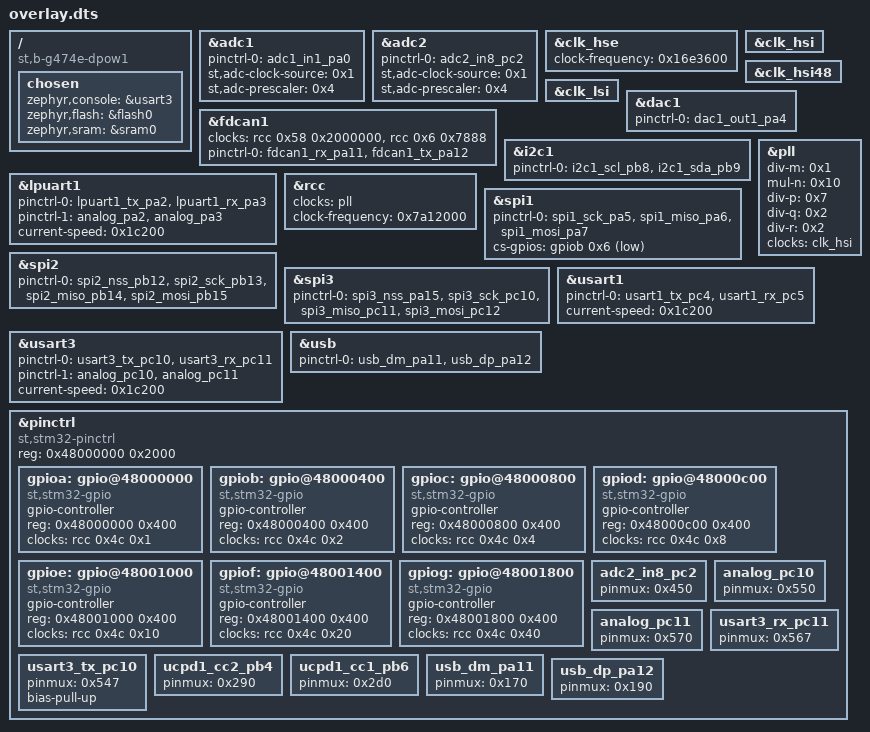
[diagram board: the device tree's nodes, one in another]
/ {
	compatible = "st,b-g474e-dpow1";
	chosen {
		zephyr,console = &usart3;
		zephyr,flash = &flash0;
		zephyr,sram = &sram0;
	};
};
&adc1{
	status = "okay";
	pinctrl-0 = < &adc1_in1_pa0 >;
	pinctrl-names = "default";
	st,adc-clock-source = < 0x1 >;
	st,adc-prescaler = < 0x4 >;
};
&adc2{
	status = "okay";
	pinctrl-0 = < &adc2_in8_pc2 >;
	pinctrl-names = "default";
	st,adc-clock-source = < 0x1 >;
	st,adc-prescaler = < 0x4 >;
	#address-cells = < 0x1 >;
	#size-cells = < 0x0 >;
};
&clk_hse{
	status = "okay";
	clock-frequency = < 0x16e3600 >;
};
&clk_hsi{
	status = "okay";
};
&clk_hsi48{
	status = "okay";
};
&clk_lsi{
	status = "okay";
};
&dac1{
	status = "okay";
	pinctrl-0 = < &dac1_out1_pa4 >;
	pinctrl-names = "default";
};
&fdcan1{
	clocks = < &rcc 0x58 0x2000000 >, < &rcc 0x6 0x7888 >;
	status = "okay";
	pinctrl-0 = < &fdcan1_rx_pa11 &fdcan1_tx_pa12 >;
	pinctrl-names = "default";
};
&i2c1{
	status = "okay";
	pinctrl-0 = < &i2c1_scl_pb8 &i2c1_sda_pb9 >;
	pinctrl-names = "default";
};
&lpuart1{
	status = "okay";
	pinctrl-0 = < &lpuart1_tx_pa2 &lpuart1_rx_pa3 >;
	pinctrl-1 = < &analog_pa2 &analog_pa3 >;
	pinctrl-names = "default", "sleep";
	current-speed = < 0x1c200 >;
};
&pll{
	status = "okay";
	div-m = < 0x1 >;
	mul-n = < 0x10 >;
	div-p = < 0x7 >;
	div-q = < 0x2 >;
	div-r = < 0x2 >;
	clocks = < &clk_hsi >;
};
&rcc{
	clocks = < &pll >;
	clock-frequency = < 0x7a12000 >;
};
&spi1{
	status = "okay";
	pinctrl-0 = < &spi1_sck_pa5 &spi1_miso_pa6 &spi1_mosi_pa7 >;
	pinctrl-names = "default";
	cs-gpios = < &gpiob 0x6 0x11 >;
};
&spi2{
	status = "okay";
	pinctrl-0 = < &spi2_nss_pb12 &spi2_sck_pb13 &spi2_miso_pb14 &spi2_mosi_pb15 >;
	pinctrl-names = "default";
};
&spi3{
	status = "okay";
	pinctrl-0 = < &spi3_nss_pa15 &spi3_sck_pc10 &spi3_miso_pc11 &spi3_mosi_pc12 >;
	pinctrl-names = "default";
};
&usart1{
	status = "okay";
	pinctrl-0 = < &usart1_tx_pc4 &usart1_rx_pc5 >;
	pinctrl-names = "default";
	current-speed = < 0x1c200 >;
};
&usart3{
	status = "okay";
	pinctrl-0 = < &usart3_tx_pc10 &usart3_rx_pc11 >;
	pinctrl-1 = < &analog_pc10 &analog_pc11 >;
	pinctrl-names = "default", "sleep";
	current-speed = < 0x1c200 >;
};
&usb{
	status = "okay";
	pinctrl-0 = < &usb_dm_pa11 &usb_dp_pa12 >;
	pinctrl-names = "default";
};
&pinctrl{
	compatible = "st,stm32-pinctrl";
	#address-cells = < 0x1 >;
	#size-cells = < 0x1 >;
	reg = < 0x48000000 0x2000 >;
	gpioa: gpio@48000000 {
		compatible = "st,stm32-gpio";
		gpio-controller;
		#gpio-cells = < 0x2 >;
		reg = < 0x48000000 0x400 >;
		clocks = < &rcc 0x4c 0x1 >;
	};
	gpiob: gpio@48000400 {
		compatible = "st,stm32-gpio";
		gpio-controller;
		#gpio-cells = < 0x2 >;
		reg = < 0x48000400 0x400 >;
		clocks = < &rcc 0x4c 0x2 >;
	};
	gpioc: gpio@48000800 {
		compatible = "st,stm32-gpio";
		gpio-controller;
		#gpio-cells = < 0x2 >;
		reg = < 0x48000800 0x400 >;
		clocks = < &rcc 0x4c 0x4 >;
	};
	gpiod: gpio@48000c00 {
		compatible = "st,stm32-gpio";
		gpio-controller;
		#gpio-cells = < 0x2 >;
		reg = < 0x48000c00 0x400 >;
		clocks = < &rcc 0x4c 0x8 >;
	};
	gpioe: gpio@48001000 {
		compatible = "st,stm32-gpio";
		gpio-controller;
		#gpio-cells = < 0x2 >;
		reg = < 0x48001000 0x400 >;
		clocks = < &rcc 0x4c 0x10 >;
	};
	gpiof: gpio@48001400 {
		compatible = "st,stm32-gpio";
		gpio-controller;
		#gpio-cells = < 0x2 >;
		reg = < 0x48001400 0x400 >;
		clocks = < &rcc 0x4c 0x20 >;
	};
	gpiog: gpio@48001800 {
		compatible = "st,stm32-gpio";
		gpio-controller;
		#gpio-cells = < 0x2 >;
		reg = < 0x48001800 0x400 >;
		clocks = < &rcc 0x4c 0x40 >;
	};
	adc2_in8_pc2: adc2_in8_pc2 {
		pinmux = < 0x450 >;
	};
	analog_pc10: analog_pc10 {
		pinmux = < 0x550 >;
	};
	analog_pc11: analog_pc11 {
		pinmux = < 0x570 >;
	};
	usart3_rx_pc11: usart3_rx_pc11 {
		pinmux = < 0x567 >;
	};
	usart3_tx_pc10: usart3_tx_pc10 {
		pinmux = < 0x547 >;
		bias-pull-up;
	};
	ucpd1_cc2_pb4: ucpd1_cc2_pb4 {
		pinmux = < 0x290 >;
	};
	ucpd1_cc1_pb6: ucpd1_cc1_pb6 {
		pinmux = < 0x2d0 >;
	};
	usb_dm_pa11: usb_dm_pa11 {
		pinmux = < 0x170 >;
	};
	usb_dp_pa12: usb_dp_pa12 {
		pinmux = < 0x190 >;
	};
};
